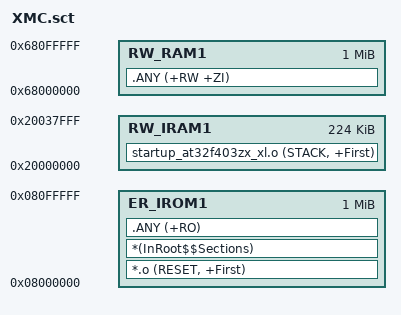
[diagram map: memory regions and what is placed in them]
; *************************************************************
; *** Scatter-Loading Description File generated by uVision ***
; *************************************************************

LR_IROM1 0x08000000 0x00100000  {    ; load region size_region
  ER_IROM1 0x08000000 0x00100000  {  ; load address = execution address
   *.o (RESET, +First)
   *(InRoot$$Sections)
   .ANY (+RO)
  }
  RW_IRAM1 0x20000000 0x00038000  {
   startup_at32f403zx_xl.o (STACK, +First) ;Set Stack to interal SARM
  }
  RW_RAM1 0x68000000 0x00100000  {  ; RW data
   .ANY (+RW +ZI)
  }
}

